# RX64M_DMAC1_Pilot register map
File version: 1.0
RX64M_DMAC1_Pilot peripheral registers generated from iodefine.h (pilot).
Registers are 8-bit, read-write, reset 0x0 unless marked. A register's access mark holds for its fields unless they carry their own. Offsets are from the block's base; lines under a group give offsets from that group; [hi:lo] are bit positions; {n}, {i} and the like mark numbered series; 'fields as' and 'values as' point back to an identical list; <NAME> marks a mode.

## Memory map
0x00082040 DMAC1 size 0x20
0x00082080 DMAC2 size 0x20
0x000820C0 DMAC3 size 0x20
0x00082100 DMAC4 size 0x20
0x00082140 DMAC5 size 0x20
0x00082180 DMAC6 size 0x20
0x000821C0 DMAC7 size 0x20

## DMAC1
Base 0x00082040
Same registers: DMAC2 0x00082080, DMAC3 0x000820C0, DMAC4 0x00082100, DMAC5 0x00082140, DMAC6 0x00082180, DMAC7 0x000821C0
0x00 DMSAR 32-bit
0x04 DMDAR 32-bit
0x08 DMCRA 32-bit
0x0C DMCRB 16-bit
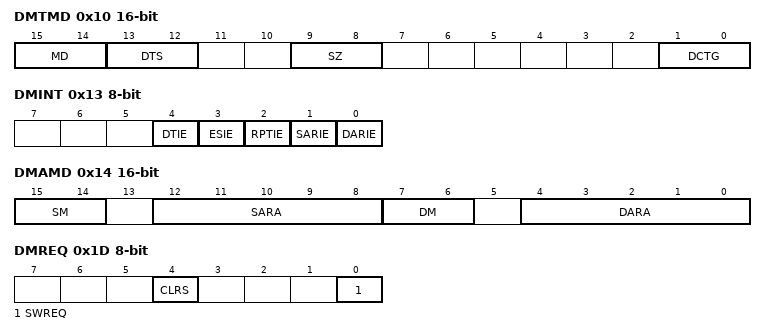
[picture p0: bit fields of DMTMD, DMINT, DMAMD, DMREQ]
0x10 DMTMD 16-bit
  [15:14] MD, [13:12] DTS, [9:8] SZ, [1:0] DCTG
0x13 DMINT
  [4] DTIE, [3] ESIE, [2] RPTIE, [1] SARIE, [0] DARIE
0x14 DMAMD 16-bit
  [15:14] SM, [12:8] SARA, [7:6] DM, [4:0] DARA
0x1C DMCNT
  [0] DTE
0x1D DMREQ
  [4] CLRS, [0] SWREQ
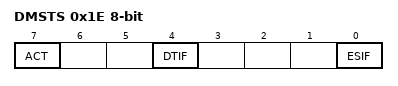
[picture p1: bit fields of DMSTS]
0x1E DMSTS
  [7] ACT, [4] DTIF, [0] ESIF
0x1F DMCSL
  [0] DISEL
